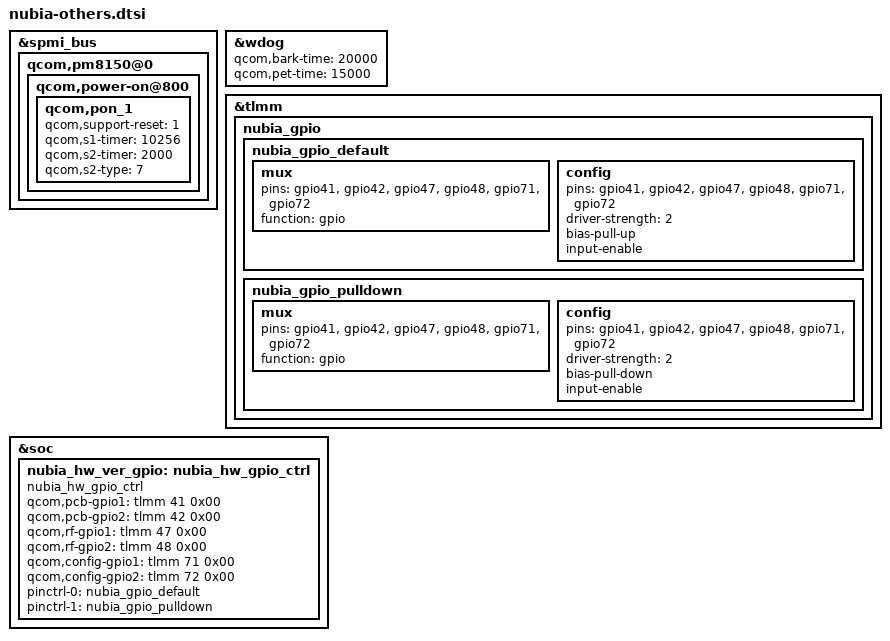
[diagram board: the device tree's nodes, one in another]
&spmi_bus {
        qcom,pm8150@0 {
                qcom,power-on@800 {
                        qcom,pon_1 {
                                qcom,support-reset = <1>;
                                qcom,s1-timer = <10256>;
                                qcom,s2-timer = <2000>;
                                qcom,s2-type = <7>;
                        };
                };
        };
};

&wdog {
        qcom,bark-time = <20000>;
        qcom,pet-time = <15000>;
};

&tlmm {
        nubia_gpio {
                nubia_gpio_default: nubia_gpio_default {
                        mux {
                                pins = "gpio41", "gpio42", "gpio47", "gpio48", "gpio71", "gpio72";
                                function = "gpio";
                        };
                        config {
                                pins = "gpio41", "gpio42", "gpio47", "gpio48", "gpio71", "gpio72";
                                driver-strength = <2>; /* 2mA */
                                bias-pull-up;
                                input-enable;
                        };
                };

                nubia_gpio_pulldown: nubia_gpio_pulldown {
                        mux {
                                pins = "gpio41", "gpio42", "gpio47", "gpio48", "gpio71", "gpio72";
                                function = "gpio";
                        };
                        config {
                                pins = "gpio41", "gpio42", "gpio47", "gpio48", "gpio71", "gpio72";
                                driver-strength = <2>; /* 2mA */
                                bias-pull-down;
                                input-enable;
                        };
                };
        };
};
&soc {
        nubia_hw_ver_gpio: nubia_hw_gpio_ctrl {
                compatible = "nubia_hw_gpio_ctrl";
                qcom,pcb-gpio1 = <&tlmm 41 0x00>;
                qcom,pcb-gpio2 = <&tlmm 42 0x00>;
                qcom,rf-gpio1 = <&tlmm 47 0x00>;
                qcom,rf-gpio2 = <&tlmm 48 0x00>;
                qcom,config-gpio1 = <&tlmm 71 0x00>;
                qcom,config-gpio2 = <&tlmm 72 0x00>;
                pinctrl-names = "pull_up_default","pull_down_default";
                pinctrl-0 = <&nubia_gpio_default>;
                pinctrl-1 = <&nubia_gpio_pulldown>;
        };
};
